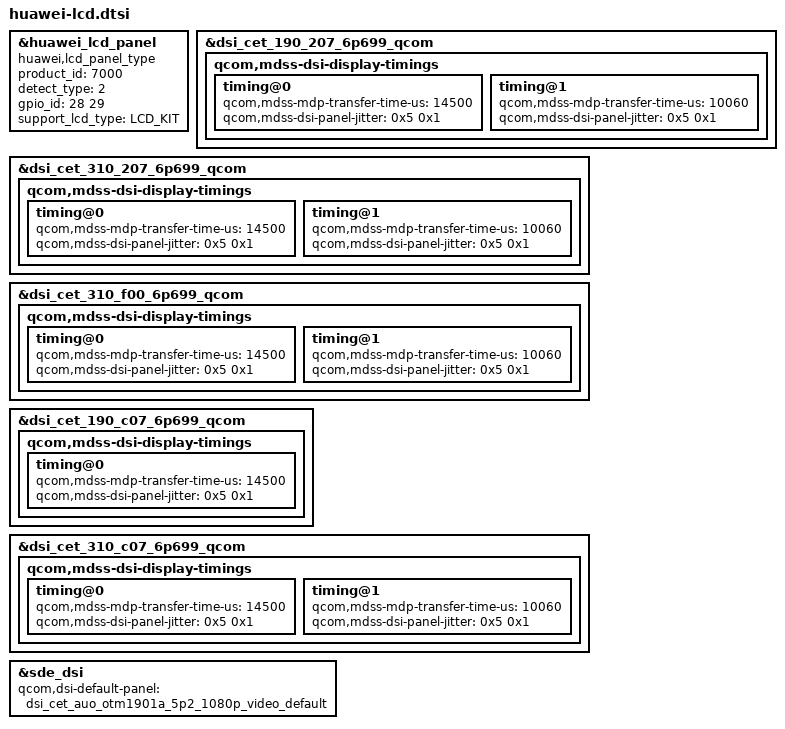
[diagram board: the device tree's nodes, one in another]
#include "../../../lcdkit3.0/cet/devkit_lcd_kit.dtsi"
&huawei_lcd_panel {
	compatible = "huawei,lcd_panel_type";
	/* auto_key_info @ name: product_id type: uint32 default: 0 */
	product_id = <7000>;
	detect_type = <2>;
	/* auto_key_info @ name: gpio_id[2] type: int default: 0 */
	gpio_id = <28 29>;
	support_lcd_type = "LCD_KIT";
};

&dsi_cet_190_207_6p699_qcom {
	qcom,mdss-dsi-display-timings {
		timing@0 {
			qcom,mdss-mdp-transfer-time-us = <14500>;
			qcom,mdss-dsi-panel-jitter = <0x5 0x1>;
		};
		timing@1 {
			qcom,mdss-mdp-transfer-time-us = <10060>;
			qcom,mdss-dsi-panel-jitter = <0x5 0x1>;
		};
	};
};

&dsi_cet_310_207_6p699_qcom {
	qcom,mdss-dsi-display-timings {
		timing@0 {
			qcom,mdss-mdp-transfer-time-us = <14500>;
			qcom,mdss-dsi-panel-jitter = <0x5 0x1>;
		};
		timing@1 {
			qcom,mdss-mdp-transfer-time-us = <10060>;
			qcom,mdss-dsi-panel-jitter = <0x5 0x1>;
		};
	};
};

&dsi_cet_310_f00_6p699_qcom {
	qcom,mdss-dsi-display-timings {
		timing@0 {
			qcom,mdss-mdp-transfer-time-us = <14500>;
			qcom,mdss-dsi-panel-jitter = <0x5 0x1>;
		};
		timing@1 {
			qcom,mdss-mdp-transfer-time-us = <10060>;
			qcom,mdss-dsi-panel-jitter = <0x5 0x1>;
		};
	};
};

&dsi_cet_190_c07_6p699_qcom {
	qcom,mdss-dsi-display-timings {
		timing@0 {
			qcom,mdss-mdp-transfer-time-us = <14500>;
			qcom,mdss-dsi-panel-jitter = <0x5 0x1>;
		};
	};
};

&dsi_cet_310_c07_6p699_qcom {
	qcom,mdss-dsi-display-timings {
		timing@0 {
			qcom,mdss-mdp-transfer-time-us = <14500>;
			qcom,mdss-dsi-panel-jitter = <0x5 0x1>;
		};
		timing@1 {
			qcom,mdss-mdp-transfer-time-us = <10060>;
			qcom,mdss-dsi-panel-jitter = <0x5 0x1>;
		};
	};
};

&sde_dsi {
	qcom,dsi-default-panel = <&dsi_cet_auo_otm1901a_5p2_1080p_video_default>;
};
